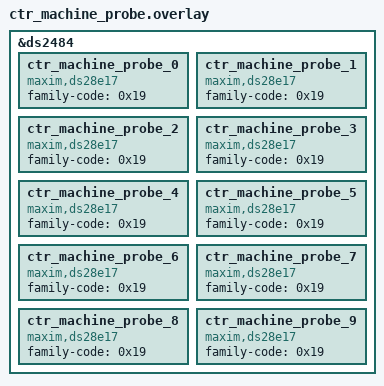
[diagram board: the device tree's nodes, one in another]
/*
 * Copyright (c) 2023 HARDWARIO a.s.
 *
 * SPDX-License-Identifier: LicenseRef-HARDWARIO-5-Clause
 */

&ds2484 {
	ctr_machine_probe_0: ctr_machine_probe_0 {
		compatible = "maxim,ds28e17";
		family-code = <0x19>;
	};
	ctr_machine_probe_1: ctr_machine_probe_1 {
		compatible = "maxim,ds28e17";
		family-code = <0x19>;
	};
	ctr_machine_probe_2: ctr_machine_probe_2 {
		compatible = "maxim,ds28e17";
		family-code = <0x19>;
	};
	ctr_machine_probe_3: ctr_machine_probe_3 {
		compatible = "maxim,ds28e17";
		family-code = <0x19>;
	};
	ctr_machine_probe_4: ctr_machine_probe_4 {
		compatible = "maxim,ds28e17";
		family-code = <0x19>;
	};
	ctr_machine_probe_5: ctr_machine_probe_5 {
		compatible = "maxim,ds28e17";
		family-code = <0x19>;
	};
	ctr_machine_probe_6: ctr_machine_probe_6 {
		compatible = "maxim,ds28e17";
		family-code = <0x19>;
	};
	ctr_machine_probe_7: ctr_machine_probe_7 {
		compatible = "maxim,ds28e17";
		family-code = <0x19>;
	};
	ctr_machine_probe_8: ctr_machine_probe_8 {
		compatible = "maxim,ds28e17";
		family-code = <0x19>;
	};
	ctr_machine_probe_9: ctr_machine_probe_9 {
		compatible = "maxim,ds28e17";
		family-code = <0x19>;
	};
};
